# ADuCM322i register map
Vendor: Analog Devices Inc.; Series: ARMCM3; File version: 1.0
CPU: CM3 r2p1, little endian, no MPU, no FPU, 3 interrupt priority bits
Registers are 16-bit, read-write, no defined reset value unless marked. A register's access mark holds for its fields unless they carry their own. Offsets are from the block's base; [hi:lo] are bit positions; {n}, {i} and the like mark numbered series; 'fields as' and 'values as' point back to an identical list.

## ID — ChipID
Base 0x40002024
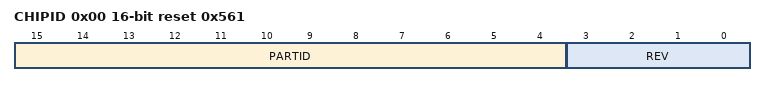
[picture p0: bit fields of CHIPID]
0x00 CHIPID ro reset 0x561 (reset mask 0x0) — Digital die ID
  [15:4] PARTID range 0x00000000..0x00000FFF — Part Identifier
  [3:0] REV range 0x00000000..0x0000000F — Silicon Revision Number

## PWRCTL — Power management
Base 0x40002400
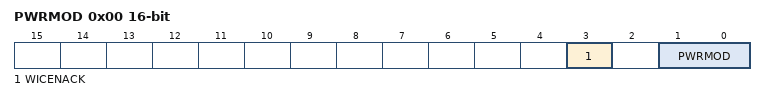
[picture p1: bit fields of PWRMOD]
0x00 PWRMOD — Power modes
  [3] WICENACK ro range 0x00000000..0x00000001 — WIC Acknowledgment for SLEEPDEEP
  [1:0] PWRMOD — Power modes control bits
    0=FULLACTIVE (Active Mode); 1=CORESLEEP (CORE_SLEEP Mode); 2=SYSSLEEP (SYS_SLEEP Mode); 3=HIBERNATE (Hibernate Mode)
0x04 PWRKEY — Key protection for PWRMOD
  [15:0] PWRKEY range 0x00000000..0x0000FFFF — Power control key register

## RESET
Base 0x40002408
0x00 RSTCFG — Reset configuration
  [0] GPIO_PLA_RETAIN — GPIO/PLA retain their status after WDT and software reset
    1=DIS (GPIO/PLA don't retain status after watchdog or software reset.); 0=EN (GPIO/PLA retain status after watchdog or software reset)
0x04 RSTKEY — Key protection for RSTCFG
  [15:0] RSTKEY range 0x00000000..0x0000FFFF — Reset configuration key register
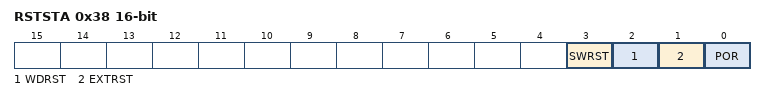
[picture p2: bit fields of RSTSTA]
0x38 RSTSTA — Reset status
  [3] SWRST range 0x00000000..0x00000001 — Software reset
  [2] WDRST range 0x00000000..0x00000001 — Watchdog timeout
  [1] EXTRST range 0x00000000..0x00000001 — External reset
  [0] POR range 0x00000000..0x00000001 — Power-on reset

## INTERRUPT — External interrupts
Base 0x40002420
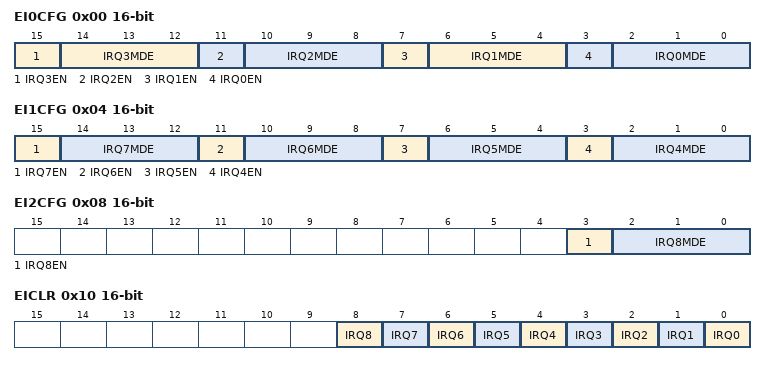
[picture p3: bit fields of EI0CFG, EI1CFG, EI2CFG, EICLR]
0x00 EI0CFG — External Interrupt configuration 0
  [15] IRQ3EN — External Interrupt 3 enable bit
    0=DIS (External Interrupt 3 disabled); 1=EN (External Interrupt 3 enabled)
  [4n+2:4n] IRQ{n}MDE (n=0..3) — External Interrupt {n} Mode registers
    0=RISE (Rising edge); 1=FALL (Falling edge); 2=RISEORFALL (Rising or falling edge); 3=HIGHLEVEL; 4=LOWLEVEL
  [11] IRQ2EN — External Interrupt 2 Enable bit
    0=DIS (External Interrupt 2 disabled); 1=EN (External Interrupt 2 enabled)
  [7] IRQ1EN — External Interrupt 1 Enable bit
    0=DIS (External Interrupt 0 disabled); 1=EN (External Interrupt 0 enabled)
  [3] IRQ0EN — External Interrupt 0 Enable bit
    values as IRQ1EN
0x04 EI1CFG — External Interrupt configuration 1
  [15] IRQ7EN — External Interrupt 7 enable bit
    0=DIS (External Interrupt 7 disabled); 1=EN (External Interrupt 7 enabled)
  [14:12] IRQ7MDE — External Interrupt 7 Mode registers
    values as EI0CFG.IRQ0MDE
  [11] IRQ6EN — External Interrupt 6 Enable bit
    0=DIS (External Interrupt 6 disabled); 1=EN (External Interrupt 6 enabled)
  [10:8] IRQ6MDE — External Interrupt 6 Mode registers
    values as EI0CFG.IRQ0MDE
  [7] IRQ5EN — External Interrupt 5 Enable bit
    0=DIS (External Interrupt 5 disabled); 1=EN (External Interrupt 5 enabled)
  [6:4] IRQ5MDE — External Interrupt 5 Mode registers
    0=RISING (Rising edge); 1=FALLING (Falling edge); 2=RISEORFALL (Rising or falling edge); 3=HIGHLEVEL; 4=LOWLEVEL
  [3] IRQ4EN — External Interrupt 4 Enable bit
    0=DIS (External Interrupt 4 disabled); 1=EN (External Interrupt 4 enabled)
  [2:0] IRQ4MDE — External Interrupt 4 Mode registers
    values as EI0CFG.IRQ0MDE
0x08 EI2CFG — External Interrupt configuration 2
  [3] IRQ8EN — External Interrupt 8 Enable bit
    0=DIS (External Interrupt 8 disabled); 1=EN (External Interrupt 8 enabled)
  [2:0] IRQ8MDE — External Interrupt 8 Mode registers
    values as EI0CFG.IRQ0MDE
0x10 EICLR — External Interrupt clear
  [n] IRQ{n} range 0x00000000..0x00000001 (n=0..8) — External interrupt {n}

## WDT — Watchdog Timer
Base 0x40002580
0x00 T3LD reset 0x1000 (reset mask 0x0) — Load value register
  [15:0] LOAD range 0x00000000..0x0000FFFF — Load value
0x04 T3VAL ro reset 0x1000 (reset mask 0x0) — Current count value register
  [15:0] CCOUNT range 0x00000000..0x0000FFFF — Current count value
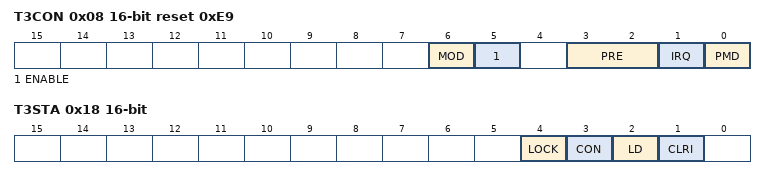
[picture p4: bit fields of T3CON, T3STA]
0x08 T3CON reset 0xE9 (reset mask 0x0) — Control register
  [6] MOD — Timer mode
    0=FREERUN (Cleared by user to operate in free running mode.); 1=PERIODIC (Set by user to operate in periodic mode (default).)
  [5] ENABLE — Timer enable
    0=DIS (Cleared by user to disable the timer.); 1=EN (Set by user to enable the timer (default).)
  [3:2] PRE — Prescaler
    0=DIV1 (Source clock/1.); 1=DIV16 (Source clock/16.); 2=DIV256 (Source clock/256 (default).); 3=DIV4096 (Source clock/4096)
  [1] IRQ — Timer interrupt
    0=DIS (Cleared by user to generate a reset on a time out (default).); 1=EN (Set by user to generate an interrupt when the timer times out. This feature is provided for debug purposes and is only available in ACTIVE mode.)
  [0] PMD — Power Mode Disable
    0=DIS (The watchdog timer will continue its count down while in hibernate mode.); 1=EN (When hibernate mode is entered, the watchdog counter will suspend its count down. As hibernate mode is exited, the count down will resume from its current count value (the count will not be reset).)
0x0C T3CLRI wo — Clear interrupt register
  [15:0] CLRWDG range 0x00000000..0x0000FFFF — Clear watchdog
0x18 T3STA ro — Status register
  [4] LOCK range 0x00000000..0x00000001 — Lock status bit
  [3] CON — T3CON write sync in progress
    0=CLR (APB and T3 clock domains T3CON configuration values match); 1=SET (APB T3CON register values are being synchronized to T3 clock domain)
  [2] LD — T3LD write sync in progress
    0=CLR (APB and T3 clock domains T3LD values match); 1=SET (APB T3LD value is being synchronized to T3 clock domain)
  [1] CLRI — T3CLRI write sync in progress
    0=CLR (APB T3CLRI write sync not done/); 1=SET (APB T3CLRI write is being synced to T3 clock domain. T3 will be restarted (if 0xCCCC was written) once sync is complete)

## Notices in the file
Copyright (C) 2014 Analog Devices Inc. Copyright (C) 2022 Sergey Koshkin
<koshkin.sergey@gmail.com> All rights reserved. Purpose: System Viewer Description
